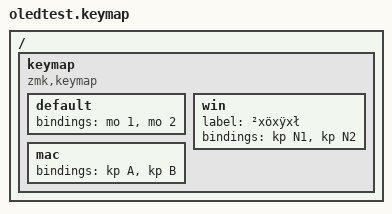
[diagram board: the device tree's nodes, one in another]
/*
 * Copyright (c) 2020 The ZMK Contributors
 *
 * SPDX-License-Identifier: MIT
 */

#include <behaviors.dtsi>
#include <dt-bindings/zmk/keys.h>

/ {
	keymap {
		compatible = "zmk,keymap";

		default {
			label = "x❖xÆx¥";
			bindings = <
				&mo 1 &mo 2
			>;
		};

		win {
			label = "²xöxÿxł";
			bindings = <
				&kp N1 &kp N2
			>;
		};

		mac {
			label = "x親おxやすみなさ";
			bindings = <
				&kp A &kp B
			>;
		};
	};
};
